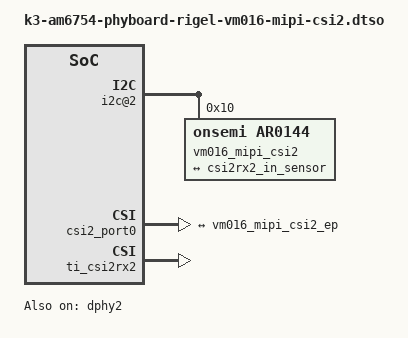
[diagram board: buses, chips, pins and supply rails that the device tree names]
// SPDX-License-Identifier: GPL-2.0-only OR MIT
/*
 * Copyright (C) 2025 PHYTEC America LLC
 * Author: Nathan Morrisson <nmorrisson@phytec.com>
 */

/dts-v1/;
/plugin/;

#include <dt-bindings/gpio/gpio.h>

&{/} {
	clk_cam_csi2: clk-cam-csi2 {
		compatible = "fixed-clock";
		#clock-cells = <0>;
		clock-frequency = <27000000>;
		status = "okay";
	};
};

&i2c_mux {
	#address-cells = <1>;
	#size-cells = <0>;

	i2c@2 {
		#address-cells = <1>;
		#size-cells = <0>;
		reg = <2>;

		vm016_mipi_csi2: camera@10 {
			compatible = "onsemi,ar0144";
			reg = <0x10>;

			clocks = <&clk_cam_csi2>;
			clock-names = "ext";

			port {
				vm016_mipi_csi2_ep: endpoint {
					remote-endpoint = <&csi2rx2_in_sensor>;
					clock-lanes = <0>;
					data-lanes = <1 2>;
					clock-noncontinuous = <1>;
					bus-type = <4>; /* MIPI_CSI2_DPHY */
					link-frequencies = /bits/ 64 <222750000>;
				};
			};
		};
	};
};

&csi2_port0 {
	status = "okay";

	csi2rx2_in_sensor: endpoint {
		remote-endpoint = <&vm016_mipi_csi2_ep>;
		bus-type = <4>; /* CSI2 DPHY. */
		clock-lanes = <0>;
		data-lanes = <1 2>;
	};
};

&dphy2 {
	status = "okay";
};

&ti_csi2rx2 {
	status = "okay";
};
